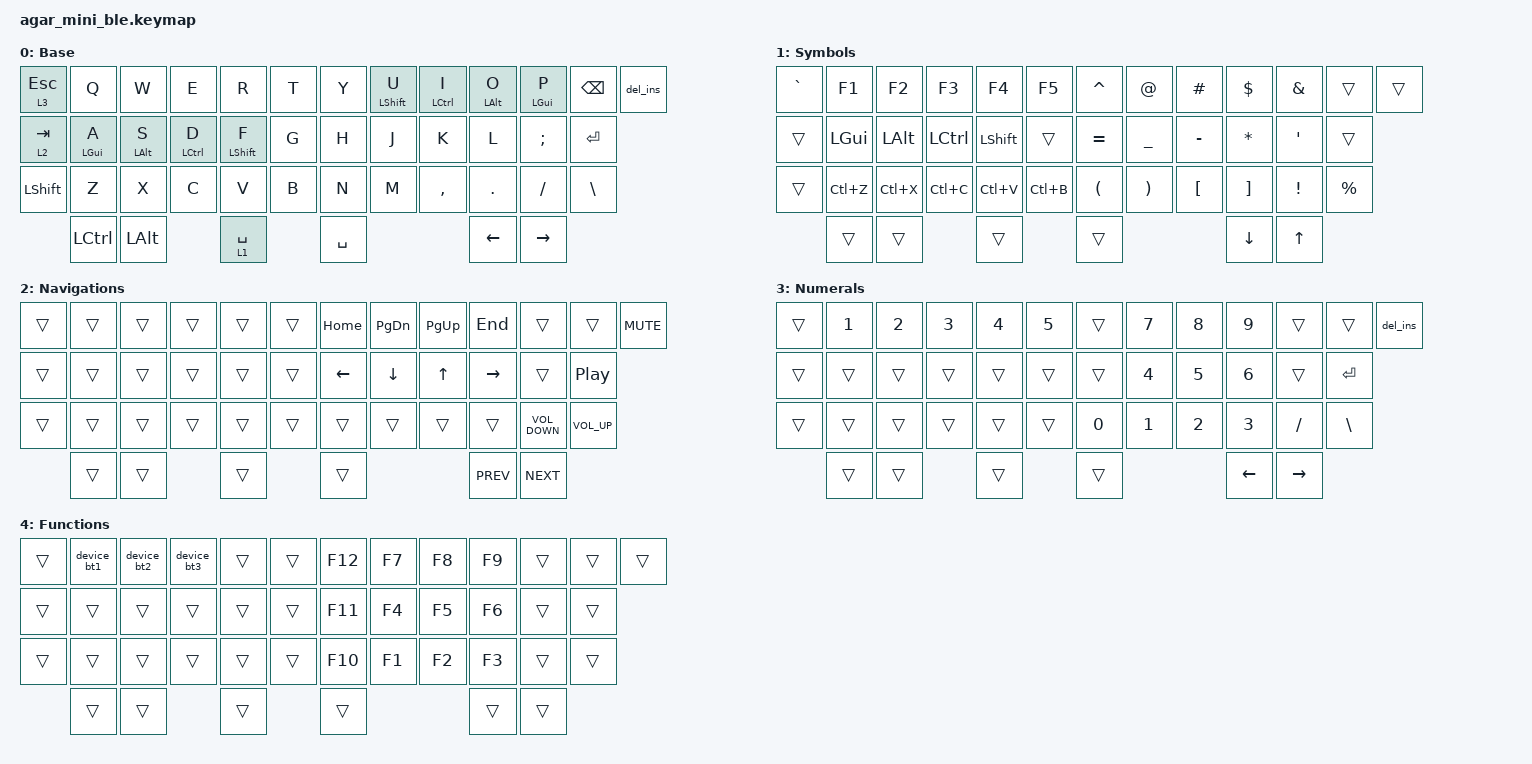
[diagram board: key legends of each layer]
/*
 * Copyright (c) 2021 The ZMK Contributors
 *
 * SPDX-License-Identifier: MIT
 */

#define FW_VER zmk_firmware_version_260830

#include <behaviors.dtsi>
#include <dt-bindings/zmk/keys.h>
#include <dt-bindings/zmk/pointing.h>
#include <dt-bindings/zmk/bt.h>
#include <dt-bindings/zmk/outputs.h>

/ {
    behaviors {
        //output ~ with RShift

        gresc: grave_escape {
            compatible = "zmk,behavior-mod-morph";
            #binding-cells = <0>;
            bindings = <&kp ESC>, <&kp GRAVE>;

            mods = <(MOD_LGUI|MOD_LSFT|MOD_RGUI|MOD_RSFT)>;
            keep-mods = <(MOD_RSFT)>;
        };

        mo: momentary_layer { display-name = "Layer Momentary"; };

        to: to_layer { display-name = "Layer To"; };

        tog: toggle_layer { display-name = "Layer Toggle"; };

        // mt default: hold preferred. Rename it.

        mt: mod_tap {
            compatible = "zmk,behavior-hold-tap";
            #binding-cells = <2>;
            flavor = "hold-preferred";
            tapping-term-ms = <260>;
            quick-tap-ms = <240>;
            bindings = <&kp>, <&kp>;

            display-name = "Mod-Tap(HP)";
        };

        // mt_tp tap preferred

        mt_tp: mod_tap_tp {
            compatible = "zmk,behavior-hold-tap";
            #binding-cells = <2>;
            flavor = "tap-preferred";
            tapping-term-ms = <200>;
            quick-tap-ms = <180>;
            bindings = <&kp>, <&kp>;

            display-name = "Mod-Tap(TP)";
        };

        // lt default: tap preferred. Rename it.

        lt: layer_tap {
            compatible = "zmk,behavior-hold-tap";
            #binding-cells = <2>;
            flavor = "tap-preferred";
            tapping-term-ms = <200>;
            quick-tap-ms = <180>;
            bindings = <&mo>, <&kp>;

            display-name = "Layer-Tap(TP)";
        };

        // lt_hp:  hold preferred

        lt_hp: layer_tap_hp {
            compatible = "zmk,behavior-hold-tap";
            #binding-cells = <2>;
            flavor = "hold-preferred";
            tapping-term-ms = <260>;
            quick-tap-ms = <240>;
            bindings = <&mo>, <&kp>;

            display-name = "Layer-Tap(HP)";
        };

        trans: transparent { display-name = "_Trans"; };

        none: none { display-name = "Key(None)"; };


        out: outputs { display-name = "zmk_reserved_output_sel"; };

        ZMK_MACRO(

        Device_USB,
        bindings = <&out OUT_USB>;

        )

        bt: bluetooth { display-name = "zmk_reserved_bluetooth"; };

        #define SHOW_LED 0xAB //A5-AF Reserved
        ZMK_MACRO(FW_VER,

        bindings = <&kp LCTRL &kp LALT &kp LSHIFT &kp LGUI &kp RCTRL &kp RALT &kp RSHIFT &kp RGUI>;

        )
        ZMK_MACRO(

        zmk_reserved_bt_clear_0,
        bindings = <&bt BT_SEL 0>, <&bt BT_CLR>, <&kp SHOW_LED>;

        )
        ZMK_MACRO(

        zmk_reserved_bt_clear_1,
        bindings = <&bt BT_SEL 1>, <&bt BT_CLR>, <&kp SHOW_LED>;

        )
        ZMK_MACRO(

        zmk_reserved_bt_clear_2,
        bindings = <&bt BT_SEL 2>, <&bt BT_CLR>, <&kp SHOW_LED>;

        )
        ZMK_MACRO(

        zmk_reserved_bt_conn_0,
        bindings = <&out OUT_BLE>, <&bt BT_SEL 0>, <&kp SHOW_LED>;

        )
        ZMK_MACRO(

        zmk_reserved_bt_conn_1,
        bindings = <&out OUT_BLE>, <&bt BT_SEL 1>, <&kp SHOW_LED>;

        )
        ZMK_MACRO(

        zmk_reserved_bt_conn_2,
        bindings = <&out OUT_BLE>, <&bt BT_SEL 2>, <&kp SHOW_LED>;

        )

        device_bt1: device_bt1 {
            compatible = "zmk,behavior-hold-tap";
            display-name = "Device_BT1";
            #binding-cells = <2>;
            flavor = "tap-preferred";
            tapping-term-ms = <3000>;  // delay amount in ms
            bindings = <&zmk_reserved_bt_clear_0>, <&zmk_reserved_bt_conn_0>;
        };

        device_bt2: device_bt2 {
            compatible = "zmk,behavior-hold-tap";
            display-name = "Device_BT2";
            #binding-cells = <2>;
            flavor = "tap-preferred";
            tapping-term-ms = <3000>;  // delay amount in ms
            bindings = <&zmk_reserved_bt_clear_1>, <&zmk_reserved_bt_conn_1>;
        };

        device_bt3: device_bt3 {
            compatible = "zmk,behavior-hold-tap";
            display-name = "Device_BT3";
            #binding-cells = <2>;
            flavor = "tap-preferred";
            tapping-term-ms = <3000>;  // delay amount in ms
            bindings = <&zmk_reserved_bt_clear_2>, <&zmk_reserved_bt_conn_2>;
        };

        soft_off: z_so_off {
            compatible = "zmk,behavior-soft-off";
            display-name = "KBD Lock";
            #binding-cells = <0>;
            hold-time-ms = <1000>;
        };

        sys_reset: sysreset { display-name = "zmk_reserved_reset"; };

        bootloader: bootload { display-name = "zmk_reserved_bootloader"; };

        bootloader_reset: bootloader_reset {
            compatible = "zmk,behavior-hold-tap";
            display-name = "RESET";
            #binding-cells = <2>;
            flavor = "tap-preferred";
            tapping-term-ms = <3000>;  // delay amount in ms
            bindings = <&bootloader>, <&sys_reset>;
        };

        studio_unlock: studio_unlock { display-name = "zmk_reserved_studio_unlock"; };

        bspc_del: backspace_delete {
            compatible = "zmk,behavior-mod-morph";
            label = "BSPC_DEL";
            bindings = <&kp BACKSPACE>, <&kp DELETE>;

            #binding-cells = <0>;
            mods = <(MOD_LSFT|MOD_RSFT)>;
        };

        del_ins: delete_insert {
            compatible = "zmk,behavior-mod-morph";
            label = "DEL_INS";
            bindings = <&kp BACKSPACE>, <&kp INSERT>;

            #binding-cells = <0>;
            mods = <(MOD_LSFT|MOD_RSFT)>;
        };

        HRL: HomeRowLeft {
            compatible = "zmk,behavior-hold-tap";
            label = "HRL";
            bindings = <&kp>, <&kp>;

            #binding-cells = <2>;
            tapping-term-ms = <200>;
            flavor = "balanced";
            hold-trigger-on-release;
            hold-trigger-key-positions = <19 6 31 32 20 7 8 21 33 34 22 9 10 23 35 40 41 42 36 24 12 11>;
        };

        HRR: HomeRowRight {
            compatible = "zmk,behavior-hold-tap";
            label = "HRR";
            bindings = <&kp>, <&kp>;

            #binding-cells = <2>;
            tapping-term-ms = <200>;
            flavor = "balanced";
            hold-trigger-on-release;
            hold-trigger-key-positions = <0 1 2 3 4 5 13 14 15 16 17 18 25 26 27 28 29 30 37 38 39>;
        };
    };

    combos {
        compatible = "zmk,combos";

        combo_caps_word {
            bindings = <&caps_word>;
            key-positions = <17 7>;
            timeout-ms = <50>;
            layers = <0>;
        };
    };
};

/ {
    keymap {
        compatible = "zmk,keymap";

        Base {
            bindings = <
&lt 3 ESCAPE  &kp Q        &kp W            &kp E                &kp R              &kp T  &kp Y      &HRR LEFT_SHIFT U  &HRR LEFT_CONTROL I  &HRR LEFT_ALT O  &HRR LGUI P    &kp BACKSPACE  &del_ins
&lt 2 TAB     &HRL LGUI A  &HRL LEFT_ALT S  &HRL LEFT_CONTROL D  &HRL LEFT_SHIFT F  &kp G  &kp H      &kp J              &kp K                &kp L            &kp SEMICOLON  &kp ENTER
&kp LSHFT     &kp Z        &kp X            &kp C                &kp V              &kp B  &kp N      &kp M              &kp COMMA            &kp DOT          &kp SLASH      &kp BACKSLASH
              &kp LCTRL    &kp LALT                              &lt 1 SPACE               &kp SPACE                                          &kp LEFT_ARROW   &kp RIGHT
            >;
        };

        Symbols {
            bindings = <
&kp GRAVE  &kp F1     &kp F2        &kp F3            &kp F4          &kp F5     &kp CARET             &kp AT                 &kp HASH          &kp DOLLAR         &kp AMPERSAND    &trans       &trans
&trans     &kp LGUI   &kp LEFT_ALT  &kp LEFT_CONTROL  &kp LEFT_SHIFT  &trans     &kp EQUAL             &kp UNDERSCORE         &kp MINUS         &kp ASTERISK       &kp APOSTROPHE   &trans
&trans     &kp LC(Z)  &kp LC(X)     &kp LC(C)         &kp LC(V)       &kp LC(B)  &kp LEFT_PARENTHESIS  &kp RIGHT_PARENTHESIS  &kp LEFT_BRACKET  &kp RIGHT_BRACKET  &kp EXCLAMATION  &kp PERCENT
           &trans     &trans                          &trans                     &trans                                                         &kp DOWN           &kp UP
            >;
        };

        Navigations {
            bindings = <
&trans  &trans  &trans  &trans  &trans  &trans  &kp HOME  &kp PAGE_DOWN  &kp PAGE_UP  &kp END     &trans             &trans            &kp C_MUTE
&trans  &trans  &trans  &trans  &trans  &trans  &kp LEFT  &kp DOWN       &kp UP       &kp RIGHT   &trans             &kp C_PLAY_PAUSE
&trans  &trans  &trans  &trans  &trans  &trans  &trans    &trans         &trans       &trans      &kp C_VOLUME_DOWN  &kp C_VOLUME_UP
        &trans  &trans          &trans          &trans                                &kp C_PREV  &kp C_NEXT
            >;
        };

        Numerals {
            bindings = <
&trans  &kp NUMBER_1  &kp NUMBER_2  &kp NUMBER_3  &kp NUMBER_4  &kp NUMBER_5  &trans        &kp NUMBER_7  &kp NUMBER_8  &kp NUMBER_9  &trans     &trans         &del_ins
&trans  &trans        &trans        &trans        &trans        &trans        &trans        &kp NUMBER_4  &kp NUMBER_5  &kp NUMBER_6  &trans     &kp ENTER
&trans  &trans        &trans        &trans        &trans        &trans        &kp NUMBER_0  &kp NUMBER_1  &kp NUMBER_2  &kp NUMBER_3  &kp SLASH  &kp BACKSLASH
        &trans        &trans                      &trans                      &trans                                    &kp LEFT      &kp RIGHT
            >;
        };

        Functions {
            bindings = <
&trans  &device_bt1  &device_bt2  &device_bt3  &trans  &trans  &kp F12  &kp F7  &kp F8  &kp F9  &trans  &trans  &trans
&trans  &trans       &trans       &trans       &trans  &trans  &kp F11  &kp F4  &kp F5  &kp F6  &trans  &trans
&trans  &trans       &trans       &trans       &trans  &trans  &kp F10  &kp F1  &kp F2  &kp F3  &trans  &trans
        &trans       &trans                    &trans          &trans                   &trans  &trans
            >;
        };
    };

    conditional_layers {
        compatible = "zmk,conditional-layers";

        symbols_numerals {
            if-layers = <1 3>;
            then-layer = <4>;
        };
    };
};
